# CMS32M67xx register map
Vendor: CMS; Series: CMS32M67xx; File version: 1.2
CPU: CM0+ r0p1, little endian, no MPU, no FPU, VTOR, 2 interrupt priority bits
Registers are 32-bit, read-write, reset 0x0 unless marked. A register's access mark holds for its fields unless they carry their own. Offsets are from the block's base; [hi:lo] are bit positions; lines under a group give offsets from that group; {n}, {i} and the like mark numbered series.

## ADCLDO
Base 0x40068340
0x00 CON0 — CON0 Description
0x04 TRIM — TRIM Description
0x0C LOCK — LOCK Description

## DIVSQRT
Base 0x40064480
Same registers: DIV 0x400644C0
0x00 CON — CON0 Description
0x04 ALUA — ALUA Description
0x08 ALUB — ALUB Description
0x0C RES0 — RES0 Description
0x10 RES1 — RES1 Description

## DAC
Base 0x40068360
0x00 CON0 — CON Description
0x04 LOCK — LOCK Description

## PGA0
Base 0x40068300
0x00 PGA0CON0 — CON0 Description
0x04 PGANCON0 — CON0 Description
0x08 PGANCON1 — CON1 Description
0x0C PGANSW — PGANSW Description
0x10 PGA0LOCK — LOCK Description

## ACMP — ACMP Decription
Base 0x40068200
0x00 C0CON0 — C0CON0 Description
0x04 C0CON1 reset 0x10 — C0CON1 Description
0x08 C1CON0 — C1CON0 Description
0x0C C1CON1 reset 0x10 — C1CON1 Description
0x10 CVECON — CVECON Description
0x14 IMSC — IMSC Description
0x18 RIS ro — RIS Description
0x1C MIS ro — MIS Description
0x20 ICLR wo — ICLR Description
0x24 ACMPOW wo — ACMPOW Description
0x28 LOCK — LOCK Description

## INT — Interrupt Controller
Base 0x40006000
{0x0+4i} IF[{i}] (i=0..31) group — Interrupt flag register
  0x00 IFL 8-bit (reset mask 0x1) — Interrupt flag register
{0x100+4i} MK[{i}] (i=0..31) group — Interrupt mask register
  0x00 MKL 8-bit reset 0xFFFFFFFF (reset mask 0x1) — Interrupt mask register

## INTM — Pin input edge detection
Base 0x40045B38
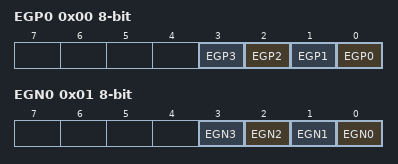
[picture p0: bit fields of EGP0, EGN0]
0x00 EGP0 8-bit — External interrupt rising edge enable register
  [n] EGP{n} (n=0..3)
0x01 EGN0 8-bit — External interrupt falling edge enable register
  [n] EGN{n} (n=0..3)

## MISC — Miscellaneous function
Base 0x40040470
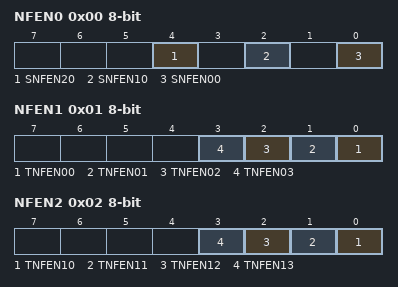
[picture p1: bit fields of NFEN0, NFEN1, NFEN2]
0x00 NFEN0 8-bit — Noise filter enable register 0
  [4] SNFEN20 — Enable noise filter of RxD2
  [2] SNFEN10 — Enable noise filter of RxD1
  [0] SNFEN00 — Enable noise filter of RxD0
0x01 NFEN1 8-bit — Noise filter enable register 1
  [n] TNFEN{n:02} (n=0..3) — Enable noise filter of TI{n:02}
0x02 NFEN2 8-bit — Noise filter enable register 2
  [n-10] TNFEN{n} (n=10..13) — Enable noise filter of TI{n}
0x03 ISC 8-bit — Input switch control register
  [7] SSIE00 — The slave select input (SS00) of SPI00 is valid
    0=INVALID (The slave select input (SS00) pin is invalid); 1=VALID (The slave select input (SS00) pin is valid)
0x04 TIOS0 8-bit (reset mask 0x83) — Timer I/O select register 0

## FMC — Flash Memory Controller
Base 0x40020000
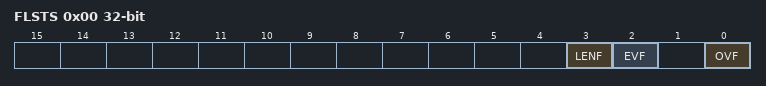
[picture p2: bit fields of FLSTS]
0x00 FLSTS — Flash status register
  [3] LENF — Flash line write error flag
  [2] EVF — Flash hardware verification error flag
  [0] OVF — Flash erase or write operaiton finish
0x04 FLOPMD1 (reset mask 0xFF) — Flash operation mode register 1
0x08 FLOPMD2 (reset mask 0xFF) — Flash operation mode register 2
0x0C FLERMD (reset mask 0x18) — Flash erase mode register
0x10 FLCERCNT (reset mask 0x800001FF) — Flash chip erase control register
0x14 FLSERCNT (reset mask 0x800001FF) — Flash sector erase control register
0x1C FLPROCNT (reset mask 0x81FF81FF) — Flash program control register
0x20 FLPROT (reset mask 0xFF) — Flash protect control register
0x20C FLRCELL (reset mask 0xFFFFFF00) — Flash new program enable register

## SAF — Flash memory CRC operation function (High-Speed CRC)
Base 0x40020100
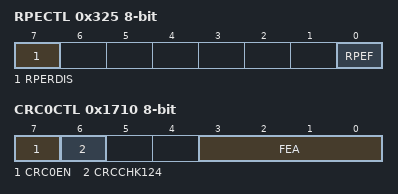
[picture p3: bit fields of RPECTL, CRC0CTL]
0x325 RPECTL 8-bit — RAM parity error control register
  [7] RPERDIS — Disable RAM parity error reset
    0=Enable parity error reset; 1=Disable parity error reset
  [0] RPEF — Parity error status flag
    0=NoError (No parity error has occurred); 1=Error (Parity error has occurred)
0x1710 CRC0CTL 8-bit — Flash memory CRC control register
  [7] CRC0EN — Control of high-speed CRC operation
  [6] CRCCHK124 — Control of high-speed CRC 124K calculus range
  [3:0] FEA — High-speed CRC operation range
0x1712 PGCRCL 16-bit — Flash memory CRC operation result register
0x20378 SFRGD 16-bit (reset mask 0xF) — SFR guard control register
0x231FA CRCD 16-bit (reset mask 0xFF) — CRC data register
0x232AC CRCIN 8-bit — CRC input register

## CRC — General Purpose CRC
Base 0x400432F0
0x0A CRCD 16-bit (reset mask 0xFF) — CRC data register
0xBC CRCIN 8-bit — CRC input register

## DBG — DBG Controller
Base 0x4001B000
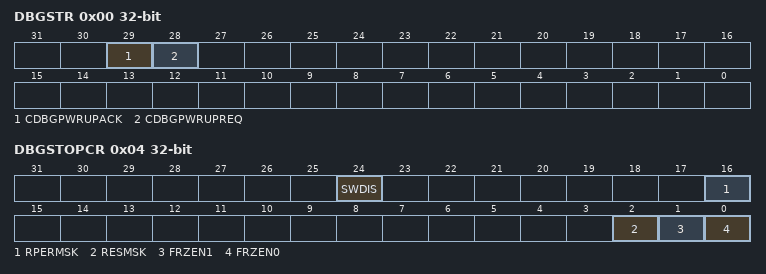
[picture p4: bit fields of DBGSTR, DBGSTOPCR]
0x00 DBGSTR ro — Debug status register
  [29] CDBGPWRUPACK — DBG Power Up Acknowledgement
  [28] CDBGPWRUPREQ — DBG Power Up Request
0x04 DBGSTOPCR — Debug Stop Control register
  [24] SWDIS — SWD Disable
  [16] RPERMSK — Mask RAM parity error in debug mode
  [2] RESMSK — Mask internal reset in debug mode
  [1] FRZEN1 — Stop Communation family macros when cpu halted
  [0] FRZEN0 — Stop Timer family macros when cpu halted

## BGR — Temperature Sensor calibration data
Base 0x00500660
0x00 VBG85 16-bit ro — The A/D conversion value of VBGR at 85 degrees and 3.0V reference voltage
0x04 VBG25 16-bit ro — The A/D conversion value of VBGR at 25 degrees and 3.0V reference voltage

## TSN — Temperature Sensor calibration data
Base 0x00500668
0x04 TSN25 16-bit ro — The A/D conversion value of Temperature Sensor at 25 degrees and 3.0V reference voltage

## UID — 128-bit Unique ID
Base 0x00500894
{0x0+4i} UID{i} (i=0..3) ro — UID word {i}

## DMA — Enhanced DMA Controller
Base 0x40005000
0x00 DMAEN0 8-bit — DMAEN0 base address register
0x08 DMABAR — DMA base address register
0x0C IFPRCR — DMA Trigger Protect register
{0x10+i} DMAIF{i} (i=0..2) 8-bit — DMA Trigger enable register {i}

## DMAVEC — DMA Vector and Control Data Area
Base 0x20001000
{0x0+i} VEC[{i}] (i=0..31) 8-bit — DMA vector area
{0x10+0x10*i} CTRL[{i}] (i=0..23) group — DMA control data area
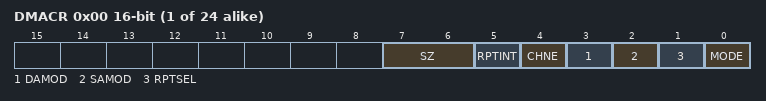
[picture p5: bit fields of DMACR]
  0x00 DMACR 16-bit — DMA Control register
    [7:6] SZ — Transfer Data size selection
      0=BYTE (8 bits); 1=HALF (16 bits); 2=WORD (32 bits)
    [5] RPTINT — Enabling/disabling repeat mode interrupts
      0=disable (Interrupt generation disabled); 1=enable (Interrupt generation enabled)
    [4] CHNE — Enabling/disabling chain transfers
      0=disable (Chain transfers disabled); 1=enable (Chain transfers enabled)
    [3] DAMOD — Destination address control
      0=Fixed; 1=Incremented
    [2] SAMOD — Source address control
      0=Fixed; 1=Incremented
    [1] RPTSEL — Repeat area selection
      0=destination (Transfer destination is the repeat area); 1=source (Transfer source is the repeat area)
    [0] MODE — Transfer mode selection
      0=Normal mode; 1=Repeat mode
  0x02 DMBLS 16-bit — DMA Block Size register
  0x04 DMACT 16-bit — DMA Transfer Count register
  0x06 DMRLD 16-bit — DMA Transfer Count Reload register
  0x08 DMSAR — DMA Source Address register
  0x0C DMDAR — DMA Destination Address register

## DMATRG — Enhanced DMA Controller
Base 0x40020D00
0x00 DMATGS — CRC data register
{0x4+4i} TGSEN{i} (i=0..2) — DMA base address register
